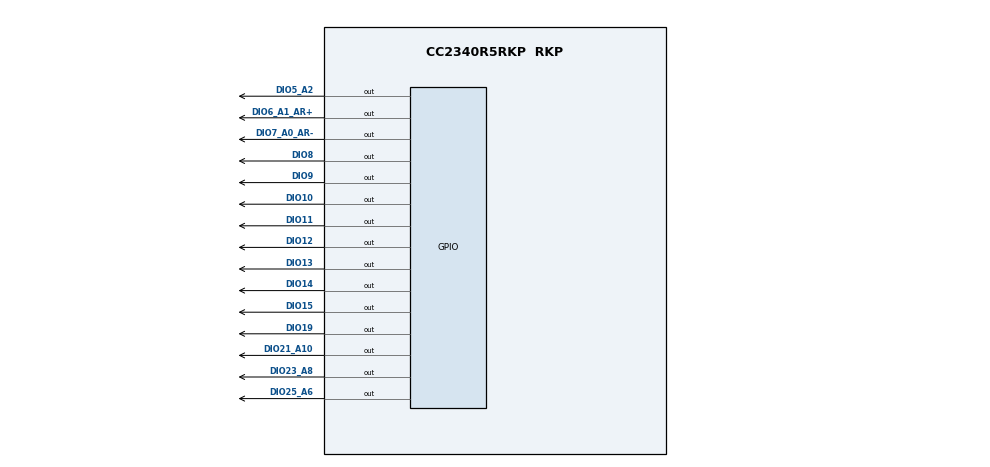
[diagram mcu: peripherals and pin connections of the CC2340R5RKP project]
/**
 * @cliArgs --device "CC2340R5RKP" --part "Default" --package "RKP" --rtos "freertos" --product "simplelink_lowpower_f3_sdk@9.11.00.18"
 * @versions {"tool":"1.23.2+4156"}
 */

/**
 * Import the modules used in this configuration.
 */
const FreeRTOS       = scripting.addModule("/freertos/FreeRTOS");
const BatteryMonitor = scripting.addModule("/ti/drivers/BatteryMonitor");
const Board          = scripting.addModule("/ti/drivers/Board");
const GPIO           = scripting.addModule("/ti/drivers/GPIO", {}, false);
const GPIO1          = GPIO.addInstance();
const GPIO2          = GPIO.addInstance();
const GPIO3          = GPIO.addInstance();
const GPIO4          = GPIO.addInstance();
const GPIO5          = GPIO.addInstance();
const GPIO6          = GPIO.addInstance();
const GPIO7          = GPIO.addInstance();
const GPIO8          = GPIO.addInstance();
const GPIO9          = GPIO.addInstance();
const GPIO10         = GPIO.addInstance();
const GPIO11         = GPIO.addInstance();
const GPIO12         = GPIO.addInstance();
const GPIO13         = GPIO.addInstance();
const GPIO14         = GPIO.addInstance();
const GPIO15         = GPIO.addInstance();
const Power          = scripting.addModule("/ti/drivers/Power");
const Temperature    = scripting.addModule("/ti/drivers/Temperature");
const Settings       = scripting.addModule("/ti/posix/freertos/Settings");

/**
 * Write custom configuration values to the imported modules.
 */
Board.generateInitializationFunctions = false;

GPIO1.mode            = "Output";
GPIO1.$name           = "CONFIG_GPIO_LED_BACKLIGHT";
GPIO1.gpioPin.$assign = "DIO15";

GPIO2.$name           = "CONFIG_GPIO_BTN_RIGHT";
GPIO2.gpioPin.$assign = "DIO9";

GPIO3.$name           = "CONFIG_GPIO_BTN_LEFT";
GPIO3.gpioPin.$assign = "DIO10";

GPIO4.$name           = "CONFIG_GPIO_COM1";
GPIO4.mode            = "Output";
GPIO4.gpioPin.$assign = "DIO8";

GPIO5.$name           = "CONFIG_GPIO_COM2";
GPIO5.mode            = "Output";
GPIO5.gpioPin.$assign = "DIO19";

GPIO6.$name           = "CONFIG_GPIO_COM3";
GPIO6.mode            = "Output";
GPIO6.gpioPin.$assign = "DIO21_A10";

GPIO7.$name           = "CONFIG_GPIO_SEG1";
GPIO7.mode            = "Output";
GPIO7.gpioPin.$assign = "DIO23_A8";

GPIO8.$name           = "CONFIG_GPIO_SEG2";
GPIO8.mode            = "Output";
GPIO8.gpioPin.$assign = "DIO25_A6";

GPIO9.$name           = "CONFIG_GPIO_SEG3";
GPIO9.mode            = "Output";
GPIO9.gpioPin.$assign = "DIO7_A0_AR-";

GPIO10.$name           = "CONFIG_GPIO_SEG4";
GPIO10.mode            = "Output";
GPIO10.gpioPin.$assign = "DIO14";

GPIO11.$name           = "CONFIG_GPIO_SEG5";
GPIO11.mode            = "Output";
GPIO11.gpioPin.$assign = "DIO6_A1_AR+";

GPIO12.$name           = "CONFIG_GPIO_SEG6";
GPIO12.mode            = "Output";
GPIO12.gpioPin.$assign = "DIO12";

GPIO13.$name           = "CONFIG_GPIO_SEG7";
GPIO13.mode            = "Output";
GPIO13.gpioPin.$assign = "DIO5_A2";

GPIO14.$name           = "CONFIG_GPIO_PWM";
GPIO14.mode            = "Output";
GPIO14.gpioPin.$assign = "DIO11";

GPIO15.$name           = "CONFIG_GPIO_PWM_N";
GPIO15.mode            = "Output";
GPIO15.gpioPin.$assign = "DIO13";

Power.policyCustomFunction = "PowerCC23X0_customPolicy";

const CCFG              = scripting.addModule("/ti/devices/CCFG", {}, false);
CCFG.ccfgTemplate.$name = "ti_devices_CCFG_CCFGCC23X0Template0";
